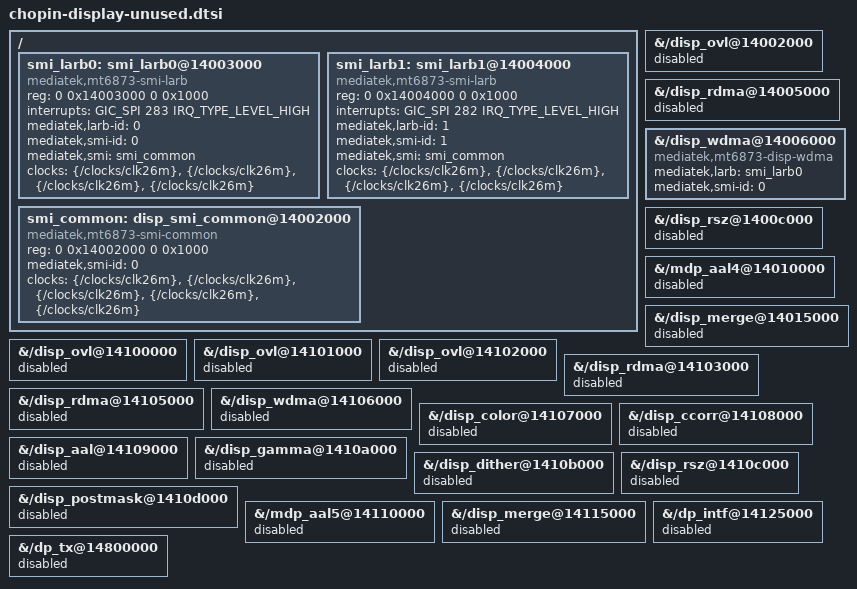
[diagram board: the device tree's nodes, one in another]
// SPDX-License-Identifier: GPL-2.0-only
/*
 * chopin: display components left disabled.
 */

&{/disp_ovl@14002000} {
	status = "disabled";
};

&{/disp_rdma@14005000} {
	status = "disabled";
};

&{/disp_wdma@14006000} {
	compatible = "mediatek,mt6873-disp-wdma";
	mediatek,larb = <&smi_larb0>;
	mediatek,smi-id = <0>;
	status = "okay";
};

&{/disp_rsz@1400c000} {
	status = "disabled";
};

&{/mdp_aal4@14010000} {
	status = "disabled";
};

&{/disp_merge@14015000} {
	status = "disabled";
};

&{/disp_ovl@14100000} {
	status = "disabled";
};

&{/disp_ovl@14101000} {
	status = "disabled";
};

&{/disp_ovl@14102000} {
	status = "disabled";
};

&{/disp_rdma@14103000} {
	status = "disabled";
};

&{/disp_rdma@14105000} {
	status = "disabled";
};

&{/disp_wdma@14106000} {
	status = "disabled";
};

&{/disp_color@14107000} {
	status = "disabled";
};

&{/disp_ccorr@14108000} {
	status = "disabled";
};

&{/disp_aal@14109000} {
	status = "disabled";
};

&{/disp_gamma@1410a000} {
	status = "disabled";
};

&{/disp_dither@1410b000} {
	status = "disabled";
};

&{/disp_rsz@1410c000} {
	status = "disabled";
};

&{/disp_postmask@1410d000} {
	status = "disabled";
};

&{/mdp_aal5@14110000} {
	status = "disabled";
};

&{/disp_merge@14115000} {
	status = "disabled";
};

&{/dp_intf@14125000} {
	status = "disabled";
};

&{/dp_tx@14800000} {
	status = "disabled";
};

/*
 * SMI larb devices for the display path, taken from the vendor base tree
 * (n10p/.../mt6873.dts).  The v2 display components resolve their larb through
 * the mediatek,larb phandle and every one of them was stuck on
 * "mtk_ddp_comp_set_larb: ... need larb device", because our DT only had the
 * upstream MT8195-family smi nodes, which the downstream SMI driver does not
 * match.  Both the vendor and the downstream compatible spellings are listed so
 * whichever the driver table prefers binds.
 */
/ {
	smi_larb0: smi_larb0@14003000 {
		compatible = "mediatek,mt6873-smi-larb", "mediatek,smi_larb0",
			     "mediatek,smi_larb";
		reg = <0 0x14003000 0 0x1000>;
		interrupts = <GIC_SPI 283 IRQ_TYPE_LEVEL_HIGH>;
		mediatek,larb-id = <0>;
		mediatek,smi-id = <0>;
		mediatek,smi = <&smi_common>;
		clocks = <&{/clocks/clk26m}>, <&{/clocks/clk26m}>, <&{/clocks/clk26m}>,
			 <&{/clocks/clk26m}>;
		clock-names = "apb", "smi", "async", "gals";
	};

	smi_larb1: smi_larb1@14004000 {
		compatible = "mediatek,mt6873-smi-larb", "mediatek,smi_larb1",
			     "mediatek,smi_larb";
		reg = <0 0x14004000 0 0x1000>;
		interrupts = <GIC_SPI 282 IRQ_TYPE_LEVEL_HIGH>;
		mediatek,larb-id = <1>;
		mediatek,smi-id = <1>;
		mediatek,smi = <&smi_common>;
		clocks = <&{/clocks/clk26m}>, <&{/clocks/clk26m}>, <&{/clocks/clk26m}>,
			 <&{/clocks/clk26m}>;
		clock-names = "apb", "smi", "async", "gals";
	};
};

/*
 * SMI common (display).  The vendor tree declares it as
 * disp_smi_common@14002000 with compatible "mediatek,disp_smi_common",
 * "mediatek,smi_common"; the downstream SMI driver needs it as the parent of
 * the larb devices, otherwise larb probe fails with -ENOENT and every v2
 * display component reports "need larb device".
 */
/ {
	smi_common: disp_smi_common@14002000 {
		compatible = "mediatek,mt6873-smi-common", "mediatek,smi_common",
			     "mediatek,disp_smi_common";
		reg = <0 0x14002000 0 0x1000>;
		mediatek,smi-id = <0>;
		clocks = <&{/clocks/clk26m}>, <&{/clocks/clk26m}>, <&{/clocks/clk26m}>,
			 <&{/clocks/clk26m}>, <&{/clocks/clk26m}>;
		clock-names = "apb", "smi", "async", "gals0", "gals1";
	};
};

/*
 * Point every display component at the larb devices that actually exist now
 * (smi_larb0@14003000 / smi_larb1@14004000).  The v2 components resolve their
 * larb through this phandle and stayed on "need larb device" while it referred
 * to the upstream MT8195 smi nodes.
 */
